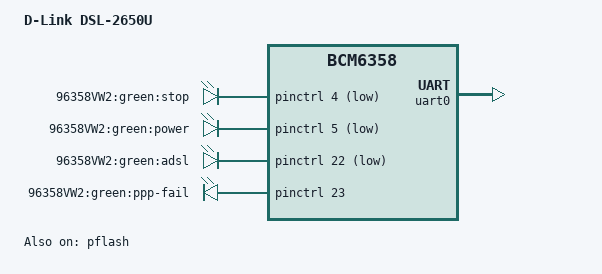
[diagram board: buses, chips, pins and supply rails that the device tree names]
/dts-v1/;

#include "bcm6358.dtsi"

#include <dt-bindings/input/input.h>

/ {
	model = "D-Link DSL-2650U";
	compatible = "d-link,dsl-2650u", "brcm,bcm6358";

	chosen {
		bootargs = "rootfstype=squashfs,jffs2 noinitrd console=ttyS0,115200";
		stdout-path = "serial0:115200n8";
	};

	gpio-leds {
		compatible = "gpio-leds";

		stop_green {
			label = "96358VW2:green:stop";
			gpios = <&pinctrl 4 1>;
		};
		power_green {
			label = "96358VW2:green:power";
			gpios = <&pinctrl 5 1>;
			default-state = "on";
		};
		adsl_green {
			label = "96358VW2:green:adsl";
			gpios = <&pinctrl 22 1>;
		};
		ppp_fail_green {
			label = "96358VW2:green:ppp-fail";
			gpios = <&pinctrl 23 0>;
		};
	};
};

&pflash {
	status = "ok";

	partitions {
		compatible = "fixed-partitions";
		#address-cells = <1>;
		#size-cells = <1>;

		cfe@0 {
			label = "CFE";
			reg = <0x000000 0x010000>;
			read-only;
		};

		linux@10000 {
			label = "linux";
			reg = <0x010000 0x7e0000>;
			compatible = "brcm,bcm963xx-imagetag";
		};

		nvram@7f0000 {
			label = "nvram";
			reg = <0x7f0000 0x010000>;
		};
	};
};

&uart0 {
	status = "ok";
};
